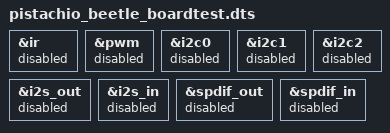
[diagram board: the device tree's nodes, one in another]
/*
 * Copyright (C) 2015 Imagination Technologies Ltd.
 * Copyright (C) 2015 Google, Inc.
 *
 * This program is free software; you can redistribute it and/or modify
 * it under the terms of the GNU General Public License version 2 as
 * published by the Free Software Foundation.
 */

#include "pistachio_beetle_mbub.dts"

&ir {
	status = "disabled";
};

&pwm {
	status = "disabled";
};

&i2c0 {
	status = "disabled";
};

&i2c1 {
	status = "disabled";
};

&i2c2 {
	status = "disabled";
};

&i2s_out {
	status = "disabled";
};

&i2s_in {
	status = "disabled";
};

&spdif_out {
	status = "disabled";
};

&spdif_in {
	status = "disabled";
};

